# ADSP-2183xW_HPC register map
Vendor: Analog Devices; Series: ADSP-2183xW_HPC; File version: 3.0.3.517
CPU: 
Registers are 32-bit, read-write, reset 0x0 unless marked. A register's access mark holds for its fields unless they carry their own. Offsets are from the block's base; [hi:lo] are bit positions; {n}, {i} and the like mark numbered series; 'fields as' and 'values as' point back to an identical list.

## EMAC0 (part 1 of 4) — RGMII, RMII, MII Ethernet Controller
Base 0x31040000
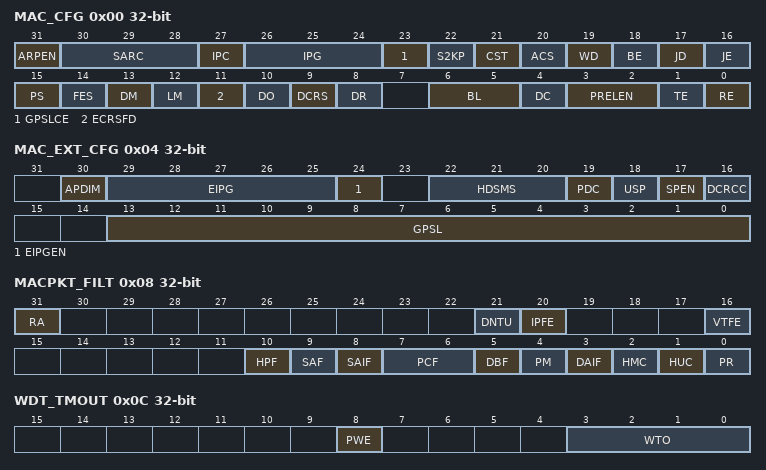
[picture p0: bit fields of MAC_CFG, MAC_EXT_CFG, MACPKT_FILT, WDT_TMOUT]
0x00 MAC_CFG — MAC Configuration Register
  [31] ARPEN — ARP Offload Enable
    0=ARPEN_DISABLE (ARP Offload is Disabled); 1=ARPEN_ENABLE (ARP Offload is Enabled)
  [30:28] SARC — Source Address Insertion or Replacement Control
    0=SA_CTRL_IN (Reserved); 2=MAC0_INS_SA (Contents of MAC Address 0 Inserted in SA Field); 3=MAC0_REP_SA (Contents of MAC Address 0 Replaces SA Field); 6=MAC1_INS_SA (Contents of MAC Address 1 Inserted in SA Field); 7=MAC1_REP_SA (Contents of MAC Address 1 Replaces SA Field)
  [27] IPC — Checksum Offload
    0=IPC_DISABLE (IP Header/payload Checksum Checking is Disabled); 1=IPC_ENABLE (IP Header/payload Checksum Checking is Enabled)
  [26:24] IPG — Inter-Packet Gap
    0=96 Bit Times IPG; 1=88 Bit Times IPG; 2=80 Bit Times IPG; 3=72 Bit Times IPG; 4=64 Bit Times IPG; 5=56 Bit Times IPG; 6=48 Bit Times IPG; 7=40 Bit Times IPG
  [23] GPSLCE — Giant Packet Size Limit Control Enable
    0=GPSLCE_DISABLE (Giant Packet Size Limit Control is Disabled); 1=GPSLCE_ENABLE (Giant Packet Size Limit Control is Enabled)
  [22] S2KP — IEEE 802.3as Support for 2K Packets
    0=S2KP_DISABLE (Support Upto 2K Packet is Disabled); 1=S2KP_ENABLE (Support Upto 2K Packet is Enabled)
  [21] CST — CRC Stripping for Type Packets
    0=CST_DISABLE (CRC Stripping for Type Packets is Disabled); 1=CST_ENABLE (CRC Stripping for Type Packets is Enabled)
  [20] ACS — Automatic Pad or CRC Stripping
    0=ACS_DISABLE (Automatic Pad or CRC Stripping is Disabled); 1=ACS_ENABLE (Automatic Pad or CRC Stripping is Enabled)
  [19] WD — Watchdog Disable
    0=WD_ENABLE (Watchdog is Enabled); 1=WD_DISABLE (Watchdog is Disabled)
  [18] BE — Packet Burst Enable
    0=BE_DISABLE (Packet Burst is Disabled); 1=BE_ENABLE (Packet Burst is Enabled)
  [17] JD — Jabber Disable
    0=JD_ENABLE (Jabber is Enabled); 1=JD_DISABLE (Jabber is Disabled)
  [16] JE — Jumbo Packet Enable
    0=JE_DISABLE (Jumbo Packet is Disabled); 1=JE_ENABLE (Jumbo Packet is Enabled)
  [15] PS — Port Select
    0=M_1000_2500M (1000 Mbps Operation); 1=M_10_100M (10 or 100 Mbps Operation)
  [14] FES — Speed
    0=M_10_1000M (10 Mbps when PS = 1; 1 Gbps when PS = 0); 1=M_100_2500M (100 Mbps when PS = 1; reserved when PS = 0)
  [13] DM — Duplex Mode
    0=HDUPLX (Half-duplex Mode); 1=FDUPLX (Full-duplex Mode)
  [12] LM — Loopback Mode
    0=LM_DISABLE (Loopback is Disabled); 1=LM_ENABLE (Loopback is Enabled)
  [11] ECRSFD — Enable Carrier Sense Before Transmission in Full-Duplex Mode
    0=ECRSFD_DISABLE (ECRSFD is Disabled); 1=ECRSFD_ENABLE (ECRSFD is Enabled)
  [10] DO — Disable Receive Own
    0=DO_ENABLE (Enable Receive Own); 1=DO_DISABLE (Disable Receive Own)
  [9] DCRS — Disable Carrier Sense During Transmission
    0=DCRS_ENABLE (Enable Carrier Sense During Transmission); 1=DCRS_DISABLE (Disable Carrier Sense During Transmission)
  [8] DR — Disable Retry
    0=DR_ENABLE (Enable Retry); 1=DR_DISABLE (Disable Retry)
  [6:5] BL — Back-Off Limit
    0=MIN_N_10 (k is Minimum of Retransmission Attempt and 10); 1=MIN_N_8 (k is Minimum of Retransmission Attempt and 8); 2=MIN_N_4 (k is Minimum of Retransmission Attempt and 4); 3=MIN_N_1 (k is Minimum of Retransmission Attempt and 1)
  [4] DC — Deferral Check
    0=DC_DISABLE (Deferral Check Function is Disabled); 1=DC_ENABLE (Deferral Check Function is Enabled)
  [3:2] PRELEN — Preamble Length for Transmit Packets
    0=M_7BYTES (7 Bytes of Preamble); 1=M_5BYTES (5 Bytes of Preamble); 2=M_3BYTES (3 Bytes of Preamble)
  [1] TE — Transmitter Enable
    0=TE_DISABLE (Transmitter is Disabled); 1=TE_ENABLE (Transmitter is Enabled)
  [0] RE — Receiver Enable
    0=RE_DISABLE (Receiver is Disabled); 1=RE_ENABLE (Receiver is Enabled)
0x04 MAC_EXT_CFG — MAC Extended Configuration Register
  [30] APDIM — ARP Packet Drop If IP Address Mismatch
    0=APDIM_DISABLE (Mux Select to Drop the Arp Packet If Target Protocol Address Mismatches IPv4 Address Disabled); 1=APDIM_ENABLE (Mux Select to Drop the Arp Packet If Target Protocol Address Mismatches IPv4 Address Enabled)
  [29:25] EIPG range 0x00000000..0x0000001F — Extended Inter-Packet Gap
  [24] EIPGEN — Extended Inter-Packet Gap Enable
    0=EIPGEN_DISABLE (Extended Inter-Packet Gap is Disabled); 1=EIPGEN_ENABLE (Extended Inter-Packet Gap is Enabled)
  [22:20] HDSMS — Maximum Size for Splitting the Header Data
    0=M_64BYTES (Maximum Size for Splitting the Header Data is 64 Bytes); 1=M_128BYTES (Maximum Size for Splitting the Header Data is 128 Bytes); 2=M_256BYTES (Maximum Size for Splitting the Header Data is 256 Bytes); 3=M_512BYTES (Maximum Size for Splitting the Header Data is 512 Bytes); 4=M_1024BYTES (Maximum Size for Splitting the Header Data is 1024 Bytes)
  [19] PDC — Packet Duplication Control
    0=PDC_DISABLE (Packet Duplication Control is Disabled); 1=PDC_ENABLE (Packet Duplication Control is Enabled)
  [18] USP — Unicast Slow Protocol Packet Detect
    0=USP_DISABLE (Unicast Slow Protocol Packet Detection is Disabled); 1=USP_ENABLE (Unicast Slow Protocol Packet Detection is Enabled)
  [17] SPEN — Slow Protocol Detection Enable
    0=SPEN_DISABLE (Slow Protocol Detection is Disabled); 1=SPEN_ENABLE (Slow Protocol Detection is Enabled)
  [16] DCRCC — Disable CRC Checking for Received Packets
    0=DCRCC_ENABLE (CRC Checking is Enabled); 1=DCRCC_DISABLE (CRC Checking is Disabled)
  [13:0] GPSL range 0x00000000..0x00003FFF — Giant Packet Size Limit
0x08 MACPKT_FILT — MAC Packet Filter Register
  [31] RA — Receive All
    0=RA_DISABLE (Receive All is Disabled); 1=RA_ENABLE (Receive All is Enabled)
  [21] DNTU — Drop Non-TCP/UDP Over IP Packets
    0=FWD (Forward Non-TCP/UDP Over IP Packets); 1=DROP (Drop Non-TCP/UDP Over IP Packets)
  [20] IPFE — Layer 3 and Layer 4 Filter Enable
    0=IPFE_DISABLE (Layer 3 and Layer 4 Filters are Disabled); 1=IPFE_ENABLE (Layer 3 and Layer 4 Filters are Enabled)
  [16] VTFE — VLAN Tag Filter Enable
    0=VTFE_DISABLE (VLAN Tag Filter is Disabled); 1=VTFE_ENABLE (VLAN Tag Filter is Enabled)
  [10] HPF — Hash or Perfect Filter
    0=HPF_DISABLE (Hash or Perfect Filter is Disabled); 1=HPF_ENABLE (Hash or Perfect Filter is Enabled)
  [9] SAF — Source Address Filter Enable
    0=SAF_DISABLE (SA Filtering is Disabled); 1=SAF_ENABLE (SA Filtering is Enabled)
  [8] SAIF — SA Inverse Filtering
    0=SAIF_DISABLE (SA Inverse Filtering is Disabled); 1=SAIF_ENABLE (SA Inverse Filtering is Enabled)
  [7:6] PCF — Pass Control Packets
    0=FLTR_ALL (MAC filters all control packets from reaching the application); 1=FW_XCPT_PAU (MAC forwards all control packets except pause packets to the application even if they fail the address filter); 2=FW_ALL (MAC forwards all control packets to the application even if they fail the address filter); 3=FW_PASS (MAC forwards the control packets that pass the address filter)
  [5] DBF — Disable Broadcast Packets
    0=DBF_ENABLE (Enable Broadcast Packets); 1=DBF_DISABLE (Disable Broadcast Packets)
  [4] PM — Pass All Multicast
    0=PM_DISABLE (Pass All Multicast is Disabled); 1=PM_ENABLE (Pass All Multicast is Enabled)
  [3] DAIF — DA Inverse Filtering
    0=DAIF_DISABLE (DA Inverse Filtering is Disabled); 1=DAIF_ENABLE (DA Inverse Filtering is Enabled)
  [2] HMC — Hash Multicast
    0=HMC_DISABLE (Hash Multicast is Disabled); 1=HMC_ENABLE (Hash Multicast is Enabled)
  [1] HUC — Hash Unicast
    0=HUC_DISABLE (Hash Unicast is Disabled); 1=HUC_ENABLE (Hash Unicast is Enabled)
  [0] PR — Promiscuous Mode
    0=PR_DISABLE (Promiscuous Mode is Disabled); 1=PR_ENABLE (Promiscuous Mode is Enabled)
0x0C WDT_TMOUT — Watchdog Timeout Register
  [8] PWE
    0=PWE_DISABLE (Programmable Watchdog is disabled.); 1=PWE_ENABLE (Programmable Watchdog is enabled.)
  [3:0] WTO
    {v}=WTO_M_{v+2}KBYTES ({v+2} KB.) (v=0..13); 14=WTO_M_16383BYTES (16383 Bytes.)
0x10 HASHTBL_REG0 — Hash Table Register 0
  [31:0] HT31T0 range 0x00000000..0xFFFFFFFF — MAC Hash Table First 32 Bits
0x14 HASHTBL_REG1 — Hash Table Register 1
  [31:0] HT63T32 range 0x00000000..0xFFFFFFFF — MAC Hash Table Second 32 Bits
0x18 HASHTBL_REG2 — Hash Table Register 2
  [31:0] HT95T64 range 0x00000000..0xFFFFFFFF — MAC Hash Table Third 32 Bits
0x1C HASHTBL_REG3 — Hash Table Register 3
  [31:0] HT127T96 range 0x00000000..0xFFFFFFFF — MAC Hash Table Fourth 32 Bits
0x20 HASHTBL_REG4 — Hash Table Register 4
  [31:0] HT159T128 range 0x00000000..0xFFFFFFFF — MAC Hash Table Fifth 32 Bits
0x24 HASHTBL_REG5 — Hash Table Register 5
  [31:0] HT191T160 range 0x00000000..0xFFFFFFFF — MAC Hash Table Sixth 32 Bits
0x28 HASHTBL_REG6 — Hash Table Register 6
  [31:0] HT223T192 range 0x00000000..0xFFFFFFFF — MAC Hash Table Seventh 32 Bits
0x2C HASHTBL_REG7 — Hash Table Register 7
  [31:0] HT255T224 range 0x00000000..0xFFFFFFFF — MAC Hash Table Eighth 32 Bits
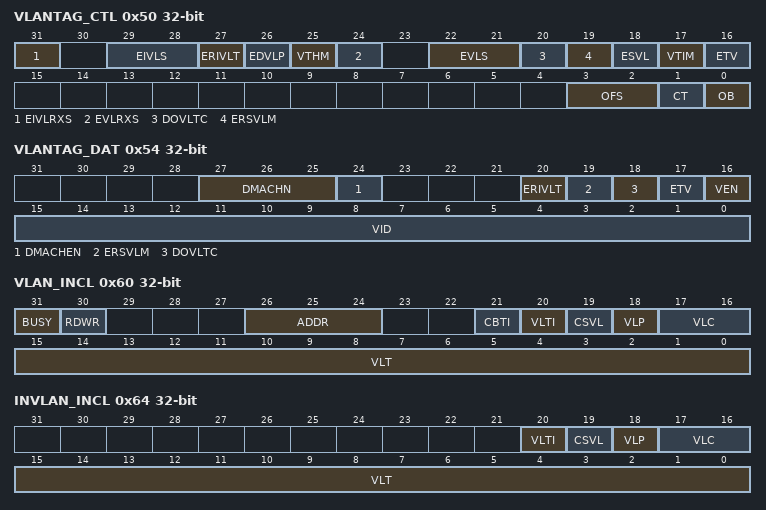
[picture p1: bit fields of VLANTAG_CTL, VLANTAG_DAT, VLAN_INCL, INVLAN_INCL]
0x50 VLANTAG_CTL — VLAN Tag Control Register
  [31] EIVLRXS — Enable Inner VLAN Tag in Rx Status
    0=EIVLRXS_DISABLE (Inner VLAN Tag in Rx Status is Disabled); 1=EIVLRXS_ENABLE (Inner VLAN Tag in Rx Status is Enabled)
  [29:28] EIVLS — Enable Inner VLAN Tag Stripping on Receive
    0=EIVLS_DONOT (Do Not Strip); 1=EIVLS_IFPASS (Strip If VLAN Filter Passes); 2=EIVLS_IFFAIL (Strip If VLAN Filter Fails); 3=EIVLS_ALWAYS (Always Strip)
  [27] ERIVLT — Enable Inner VLAN Tag Comparison
    0=ERIVLT_DISABLE (Inner VLAN Tag is Disabled); 1=ERIVLT_ENABLE (Inner VLAN Tag is Enabled)
  [26] EDVLP — Enable Double VLAN Processing
    0=EDVLP_DISABLE (Double VLAN Processing is Disabled); 1=EDVLP_ENABLE (Double VLAN Processing is Enabled)
  [25] VTHM — VLAN Tag Hash Table Match Enable
    0=VTHM_DISABLE (VLAN Tag Hash Table Match is Disabled); 1=VTHM_ENABLE (VLAN Tag Hash Table Match is Enabled)
  [24] EVLRXS — Enable VLAN Tag in Rx Status
    0=EVLRXS_DISABLE (VLAN Tag in Rx Status is Disabled); 1=EVLRXS_ENABLE (VLAN Tag in Rx Status is Enabled)
  [22:21] EVLS — Enable VLAN Tag Stripping on Receive
    0=EVLS_DONOT (Do Not Strip); 1=EVLS_IFPASS (Strip If VLAN Filter Passes); 2=EVLS_IFFAIL (Strip If VLAN Filter Fails); 3=EVLS_ALWAYS (Always Strip)
  [20] DOVLTC — Disable VLAN Type Check for VLAN Hash Filtering
    0=DOVLTC_ENABLE (VLAN Type Check is Enabled); 1=DOVLTC_DISABLE (VLAN Type Check is Disabled)
  [19] ERSVLM — Enable Receive S-VLAN Match for VLAN Hash Filtering
    0=ERSVLM_DISABLE (Receive S-VLAN Match is Disabled); 1=ERSVLM_ENABLE (Receive S-VLAN Match is Enabled)
  [18] ESVL — Enable S-VLAN
    0=ESVL_DISABLE (S-VLAN is Disabled); 1=ESVL_ENABLE (S-VLAN is Enabled)
  [17] VTIM — VLAN Tag Inverse Match Enable
    0=VTIM_DISABLE (VLAN Tag Inverse Match is Disabled); 1=VTIM_ENABLE (VLAN Tag Inverse Match is Enabled)
  [16] ETV — Enable 12-Bit VLAN Tag Comparison for VLAN Hash Filtering
    0=ETV_DISABLE (12-Bit VLAN Tag Comparison is Disabled); 1=ETV_ENABLE (12-Bit VLAN Tag Comparison is Enabled)
  [3:2] OFS range 0x00000000..0x00000003 — Offset
  [1] CT — Command Type
    0=WRITE (Write Operation); 1=READ (Read Operation)
  [0] OB — Operation Busy
    0=OB_DISABLE (Operation Busy is Disabled); 1=OB_ENABLE (Operation Busy is Enabled)
0x54 VLANTAG_DAT — VLAN Tag Indirect Access Data Register
  [27:25] DMACHN range 0x00000000..0x00000007 — DMA Channel Number
  [24] DMACHEN — DMA Channel Number Enable
    0=DMACHEN_DISABLE (DMA Channel Number is Disabled); 1=DMACHEN_ENABLE (DMA Channel Number is Enabled)
  [20] ERIVLT — Enable Inner VLAN Tag Comparison
    0=ERIVLT_DISABLE (Inner VLAN Tag Comparison is Disabled); 1=ERIVLT_ENABLE (Inner VLAN Tag Comparison is Enabled)
  [19] ERSVLM — Enable S-VLAN Match for Received Frames
    values as VLANTAG_CTL.ERSVLM
  [18] DOVLTC — Disable VLAN Type Comparison
    0=DOVLTC_ENABLE (VLAN Type Comparison is Enabled); 1=DOVLTC_DISABLE (VLAN Type Comparison is Disabled)
  [17] ETV — 12bits or 16bits VLAN Comparison
    0=M_16BIT (16 Bit VLAN Comparison); 1=M_12BIT (12 Bit VLAN Comparison)
  [16] VEN — VLAN Tag Enable
    0=VEN_DISABLE (VLAN Tag is Disabled); 1=VEN_ENABLE (VLAN Tag is Enabled)
  [15:0] VID range 0x00000000..0x0000FFFF — VLAN Tag ID
0x58 VLAN_HASHTBL — VLAN Hash Table Register
  [15:0] VLHT range 0x00000000..0x0000FFFF — VLAN Hash Table
0x60 VLAN_INCL — VLAN Tag Inclusion or Replacement Register
  [31] BUSY ro
    0=BUSY_INACTIVE (Busy Status Not Detected); 1=BUSY_ACTIVE (Busy Status Detected)
  [30] RDWR — Read Write Control
    0=READ (Read Operation of Indirect Access); 1=WRITE (Write Operation of Indirect Access)
  [26:24] ADDR range 0x00000000..0x00000007 — Address
  [21] CBTI — Channel Based Tag Insertion
    0=CBTI_DISABLE (Channel Based Tag Insertion is Disabled); 1=CBTI_ENABLE (Channel Based Tag Insertion is Enabled)
  [20] VLTI — VLAN Tag Input
    0=VLTI_DISABLE (VLAN Tag Input is Disabled); 1=VLTI_ENABLE (VLAN Tag Input is Enabled)
  [19] CSVL — C-VLAN or S-VLAN
    0=CVLAN (C-VLAN Type (0x8100) is Inserted or Replaced); 1=SVLAN (S-VLAN Type (0x88A8) is Inserted or Replaced)
  [18] VLP — VLAN Priority Control
    0=VLP_DISABLE (VLAN Priority Control is Disabled); 1=VLP_ENABLE (VLAN Priority Control is Enabled)
  [17:16] VLC — VLAN Tag Control in Transmit Packets
    0=NONE (No VLAN Tag Deletion, Insertion, or Replacement); 1=DELETE (VLAN Tag Deletion); 2=INSERT (VLAN Tag Insertion); 3=REPLACE (VLAN Tag Replacement)
  [15:0] VLT range 0x00000000..0x0000FFFF — VLAN Tag for Transmit Packets
0x64 INVLAN_INCL — Inner VLAN Tag Inclusion or Replacement Register
  [20] VLTI — VLAN Tag Input
    values as VLAN_INCL.VLTI
  [19] CSVL — C-VLAN or S-VLAN
    0=CVLAN (C-VLAN Type (0x8100) is Inserted); 1=SVLAN (S-VLAN Type (0x88A8) is Inserted)
  [18] VLP — VLAN Priority Control
    values as VLAN_INCL.VLP
  [17:16] VLC — VLAN Tag Control in Transmit Packets
    values as VLAN_INCL.VLC
  [15:0] VLT range 0x00000000..0x0000FFFF — VLAN Tag for Transmit Packets
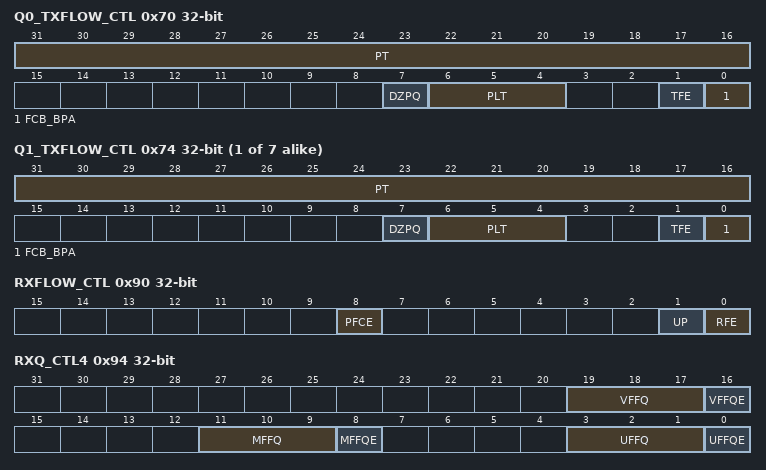
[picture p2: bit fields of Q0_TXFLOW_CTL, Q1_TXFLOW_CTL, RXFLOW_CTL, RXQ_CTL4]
0x70 Q0_TXFLOW_CTL — Queue 0 Transmit Flow Control Register
  [31:16] PT range 0x00000000..0x0000FFFF — Pause Time
  [7] DZPQ — Disable Zero-Quanta Pause
    0=DZPQ_ENABLE (Zero-Quanta Pause Packet Generation is Enabled); 1=DZPQ_DISABLE (Zero-Quanta Pause Packet Generation is Disabled)
  [6:4] PLT — Pause Low Threshold
    0=PT4 (Pause Time Minus 4 Slot Times); 1=PT28 (Pause Time Minus 28 Slot Times); 2=PT36 (Pause Time Minus 36 Slot Times); 3=PT144 (Pause Time Minus 144 Slot Times); 4=PT256 (Pause Time Minus 256 Slot Times); 5=PT512 (Pause Time Minus 512 Slot Times)
  [1] TFE — Transmit Flow Control Enable
    0=TFE_DISABLE (Transmit Flow Control is Disabled); 1=TFE_ENABLE (Transmit Flow Control is Enabled)
  [0] FCB_BPA — Flow Control Busy or Backpressure Activate
    0=FCB_BPA_DISABLE (Flow Control Busy or Backpressure Activate is Disabled); 1=FCB_BPA_ENABLE (Flow Control Busy or Backpressure Activate is Enabled)
{0x70+4i} Q{i}_TXFLOW_CTL (i=1..7) — Queue [i] Transmit Flow Control Register
  [31:16] PT range 0x00000000..0x0000FFFF — Pause Time
  [7] DZPQ — Disable Zero-Quanta Pause
    values as Q0_TXFLOW_CTL.DZPQ
  [6:4] PLT — Pause Low Threshold
    0=PT4 (PT - 4 Slot Times); 1=PT28 (PT - 28 Slot Times); 2=PT36 (PT - 36 Slot Times); 3=PT144 (PT - 144 Slot Times); 4=PT256 (PT - 256 Slot Times); 5=PT512 (PT - 512 Slot Times)
  [1] TFE — Transmit Flow Control Enable
    values as Q0_TXFLOW_CTL.TFE
  [0] FCB_BPA — Flow Control Busy
    values as Q0_TXFLOW_CTL.FCB_BPA
0x90 RXFLOW_CTL — Receive Flow Control Register
  [8] PFCE — Priority Based Flow Control Enable
    0=PFCE_DISABLE (Priority Based Flow Control is Disabled); 1=PFCE_ENABLE (Priority Based Flow Control is Enabled)
  [1] UP — Unicast Pause Packet Detect
    0=UP_DISABLE (Unicast Pause Packet Detect Disabled); 1=UP_ENABLE (Unicast Pause Packet Detect Enabled)
  [0] RFE — Receive Flow Control Enable
    0=RFE_DISABLE (Receive Flow Control is Disabled); 1=RFE_ENABLE (Receive Flow Control is Enabled)
0x94 RXQ_CTL4 — Receive Queue Control 4 Register
  [19:17] VFFQ range 0x00000000..0x00000007 — VLAN Tag Filter Fail Packets Queue
  [16] VFFQE — VLAN Tag Filter Fail Packets Queuing Enable
    0=VFFQE_DISABLE (VLAN Tag Filter Fail Packets Queuing is Disabled); 1=VFFQE_ENABLE (VLAN Tag Filter Fail Packets Queuing is Enabled)
  [11:9] MFFQ range 0x00000000..0x00000007 — Multicast Address Filter Fail Packets Queue.
  [8] MFFQE — Multicast Address Filter Fail Packets Queuing Enable.
    0=MFFQE_DISABLE (Multicast Address Filter Fail Packets Queuing is Disabled); 1=MFFQE_ENABLE (Multicast Address Filter Fail Packets Queuing is Enabled)
  [3:1] UFFQ range 0x00000000..0x00000007 — Unicast Address Filter Fail Packets Queue.
  [0] UFFQE — Unicast Address Filter Fail Packets Queuing Enable.
    0=UFFQE_DISABLE (Unicast Address Filter Fail Packets Queuing is Disabled); 1=UFFQE_ENABLE (Unicast Address Filter Fail Packets Queuing is Enabled)
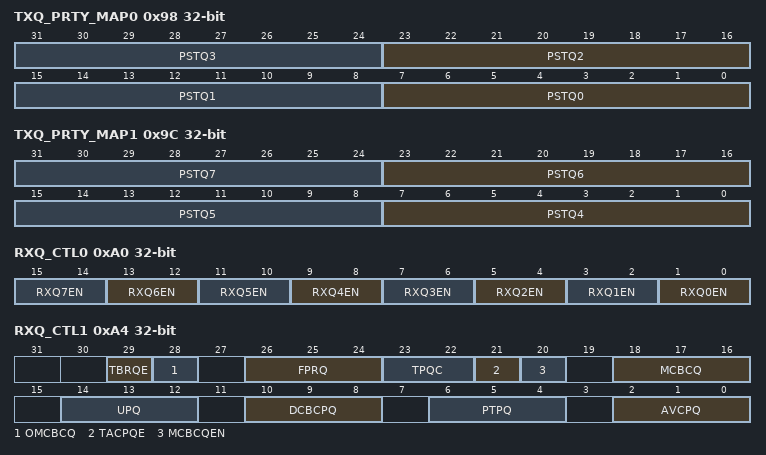
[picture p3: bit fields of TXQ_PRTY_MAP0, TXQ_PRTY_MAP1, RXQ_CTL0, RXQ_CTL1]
0x98 TXQ_PRTY_MAP0 — Transmit Queue Priority Mapping 0 Register
  [8n+7:8n] PSTQ{n} range 0x00000000..0x000000FF (n=0..3) — Priorities Selected in Transmit Queue {n}
0x9C TXQ_PRTY_MAP1 — Transmit Queue Priority Mapping 1 Register
  [8n-25:8n-32] PSTQ{n} range 0x00000000..0x000000FF (n=4..7) — Priorities Selected in Transmit Queue {n}
0xA0 RXQ_CTL0 — Receive Queue Control 0 Register
  [2n+1:2n] RXQ{n}EN (n=0..7) — Receive Queue {n} Enable
    0=RXQ{n}EN_DISABLE (Queue Not Enabled); 1=RXQ{n}EN_EN_AV (Queue Enabled for AV); 2=RXQ{n}EN_EN_DCB_GEN (Queue Enabled for DCB/Generic)
0xA4 RXQ_CTL1 — Receive Queue Control 1 Register
  [29] TBRQE range 0x00000000..0x00000001 — Type Field Based Rx Queuing Enable
  [28] OMCBCQ — Over-riding MC-BC Queue Priority Select
    0=OMCBCQ_DISABLE (Overriding MCBCQ Priority Disabled); 1=OMCBCQ_ENABLE (Overriding MCBCQ Priority Enabled)
  [26:24] FPRQ range 0x00000000..0x00000007 — Frame Preemption Residue Queue
  [23:22] TPQC range 0x00000000..0x00000003 — Tagged PTP Over Ethernet Packets Queuing Control.
  [21] TACPQE — Tagged AV Control Packets Queuing Enable.
    0=TACPQE_DISABLE (Tagged AV Control Packets Queuing is Disabled); 1=TACPQE_ENABLE (Tagged AV Control Packets Queuing is Enabled)
  [20] MCBCQEN — Multicast and Broadcast Queue Enable
    0=MCBCQEN_DISABLE (Multicast and Broadcast Queue is Disabled); 1=MCBCQEN_ENABLE (Multicast and Broadcast Queue is Enabled)
  [18:16] MCBCQ — Multicast and Broadcast Queue
    {v}=MCBCQ_QUEUE{v} (Receive Queue {v}) (v=0..7)
  [14:12] UPQ — Untagged Packet Queue
    {v}=UPQ_QUEUE{v} (Receive Queue {v}) (v=0..7)
  [10:8] DCBCPQ — DCB Control Packets Queue
    {v}=DCBCPQ_QUEUE{v} (Receive Queue {v}) (v=0..7)
  [6:4] PTPQ — PTP Packets Queue
    {v}=PTPQ_QUEUE{v} (Receive Queue {v}) (v=0..7)
  [2:0] AVCPQ — AV Untagged Control Packets Queue
    {v}=AVCPQ_QUEUE{v} (Receive Queue {v}) (v=0..7)
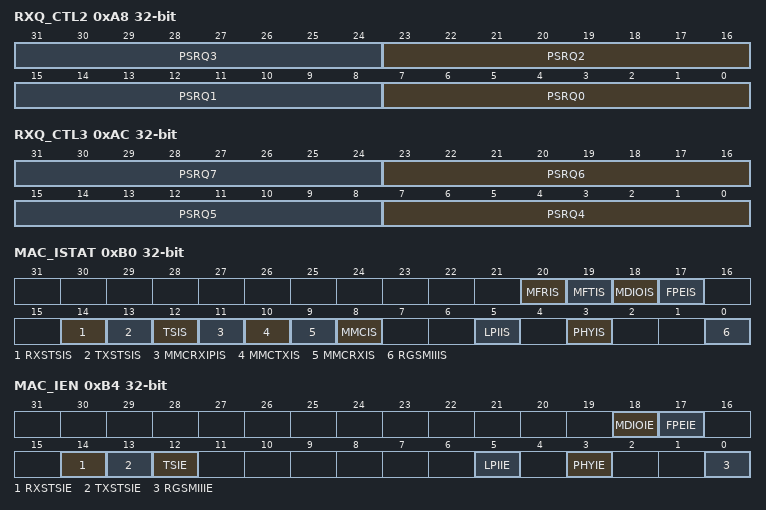
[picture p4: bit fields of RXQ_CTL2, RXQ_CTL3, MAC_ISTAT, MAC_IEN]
0xA8 RXQ_CTL2 — Receive Queue Control 2 Register
  [8n+7:8n] PSRQ{n} range 0x00000000..0x000000FF (n=0..3) — Priorities Selected in the Receive Queue {n}
0xAC RXQ_CTL3 — Receive Queue Control 3 Register
  [8n-25:8n-32] PSRQ{n} range 0x00000000..0x000000FF (n=4..7) — Priorities Selected in the Receive Queue {n}
0xB0 MAC_ISTAT — MAC Interrupt Status Register
  [20] MFRIS ro — MMC FPE Receive Interrupt Status
    0=MFRIS_INACTIVE (MMC FPE Receive Interrupt Status Not Active); 1=MFRIS_ACTIVE (MMC FPE Receive Interrupt Status Active)
  [19] MFTIS ro — MMC FPE Transmit Interrupt Status
    0=MFTIS_INACTIVE (MMC FPE Transmit Interrupt Status Not Active); 1=MFTIS_ACTIVE (MMC FPE Transmit Interrupt Status Active)
  [18] MDIOIS ro — MDIO Interrupt Status
    0=MDIOIS_INACTIVE (MDIO Interrupt Status Not Active); 1=MDIOIS_ACTIVE (MDIO Interrupt Status Active)
  [17] FPEIS ro — Frame Preemption Interrupt Status
    0=FPEIS_INACTIVE (Frame Preemption Interrupt Status Not Active); 1=FPEIS_ACTIVE (Frame Preemption Interrupt Status Active)
  [14] RXSTSIS ro — Receive Status Interrupt
    0=RXSTSIS_INACTIVE (Receive Interrupt Status Not Active); 1=RXSTSIS_ACTIVE (Receive Interrupt Status Active)
  [13] TXSTSIS ro — Transmit Status Interrupt
    0=TXSTSIS_INACTIVE (Status Not Active); 1=TXSTSIS_ACTIVE (Status Active)
  [12] TSIS ro — Time Stamp Interrupt Status
    0=TSIS_INACTIVE (Status Not Active); 1=TSIS_ACTIVE (Status Active)
  [11] MMCRXIPIS ro — MMC Receive Checksum Offload Interrupt Status
    0=MMCRXIPIS_INACTIVE (MMC Receive Checksum Offload Interrupt Status Not Active); 1=MMCRXIPIS_ACTIVE (MMC Receive Checksum Offload Interrupt Status Active)
  [10] MMCTXIS ro — MMC Transmit Interrupt Status
    0=MMCTXIS_INACTIVE (MMC Transmit Interrupt Status Not Active); 1=MMCTXIS_ACTIVE (MMC Transmit Interrupt Status Active)
  [9] MMCRXIS ro — MMC Receive Interrupt Status
    0=MMCRXIS_INACTIVE (MMC Receive Interrupt Status Not Active); 1=MMCRXIS_ACTIVE (MMC Receive Interrupt Status Active)
  [8] MMCIS ro — MMC Interrupt Status
    0=MMCIS_INACTIVE (MMC Interrupt Status Not Active); 1=MMCIS_ACTIVE (MMC Interrupt Status Active)
  [5] LPIIS ro — LPI Interrupt Status
    0=LPIIS_INACTIVE (LPI Interrupt Status Not Active); 1=LPIIS_ACTIVE (LPI Interrupt Status Active)
  [3] PHYIS ro — PHY Interrupt
    0=PHYIS_INACTIVE (PHY Interrupt Not Detected); 1=PHYIS_ACTIVE (PHY Interrupt Detected)
  [0] RGSMIIIS ro — RGMII or SMII Interrupt Status
    0=RGSMIIIS_INACTIVE (RGMII or SMII Interrupt Status is Not Active); 1=RGSMIIIS_ACTIVE (RGMII or SMII Interrupt Status is Active)
0xB4 MAC_IEN — MAC Interrupt Enable Register
  [18] MDIOIE — MDIO Interrupt Enable
    0=MDIOIE_DISABLE (MDIO Interrupt is Disabled); 1=MDIOIE_ENABLE (MDIO Interrupt is Enabled)
  [17] FPEIE — Frame Preemption Interrupt Enable
    0=FPEIE_DISABLE (Frame Preemption Interrupt is Disabled); 1=FPEIE_ENABLE (Frame Preemption Interrupt is Enabled)
  [14] RXSTSIE — Receive Status Interrupt Enable
    0=RXSTSIE_DISABLE (Receive Status Interrupt is Disabled); 1=RXSTSIE_ENABLE (Receive Status Interrupt is Enabled)
  [13] TXSTSIE — Transmit Status Interrupt Enable
    0=TXSTSIE_DISABLE (Disable); 1=TXSTSIE_ENABLE (Enable)
  [12] TSIE — Timestamp Interrupt Enable
    0=TSIE_DISABLE (Disable); 1=TSIE_ENABLE (Enable)
  [5] LPIIE — LPI Interrupt Enable
    0=LPIIE_DISABLE (LPI Interrupt is Disabled); 1=LPIIE_ENABLE (LPI Interrupt is Enabled)
  [3] PHYIE — PHY Interrupt Enable
    0=PHYIE_DISABLE (PHY Interrupt is Disabled); 1=PHYIE_ENABLE (PHY Interrupt is Enabled)
  [0] RGSMIIIE — RGMII or SMII Interrupt Enable
    0=RGSMIIIE_DISABLE (RGMII or SMII Interrupt is Disabled); 1=RGSMIIIE_ENABLE (RGMII or SMII Interrupt is Enabled)
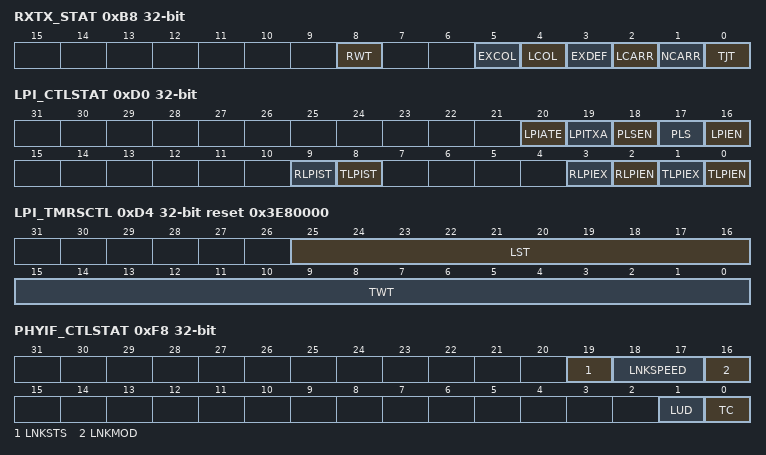
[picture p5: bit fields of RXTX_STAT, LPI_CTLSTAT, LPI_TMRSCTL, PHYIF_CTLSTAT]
0xB8 RXTX_STAT — Receive Transmit Status Register
  [8] RWT ro — Receive Watchdog Timeout
    0=RWT_INACTIVE (No Receive Watchdog Timeout); 1=RWT_ACTIVE (Receive Watchdog Timed Out)
  [5] EXCOL ro — Excessive Collisions
    0=EXCOL_INACTIVE (No Collision); 1=EXCOL_ACTIVE (Excessive Collision is Sensed)
  [4] LCOL ro — Late Collision
    0=LCOL_INACTIVE (No Collision); 1=LCOL_ACTIVE (Late Collision is Sensed)
  [3] EXDEF ro — Excessive Deferral
    0=EXDEF_INACTIVE (No Excessive Deferral); 1=EXDEF_ACTIVE (Excessive Deferral)
  [2] LCARR ro — Loss of Carrier
    0=LCARR_INACTIVE (Carrier is Present); 1=LCARR_ACTIVE (Loss of Carrier)
  [1] NCARR ro — No Carrier
    0=NCARR_INACTIVE (Carrier is Present); 1=NCARR_ACTIVE (No Carrier)
  [0] TJT ro — Transmit Jabber Timeout
    0=TJT_INACTIVE (No Transmit Jabber Timeout); 1=TJT_ACTIVE (Transmit Jabber Timeout Occurred)
0xD0 LPI_CTLSTAT — LPI Control and Status Register
  [20] LPIATE — LPI Timer Enable
    0=LPIATE_DISABLE (LPI Timer is Disabled); 1=LPIATE_ENABLE (LPI Timer is Enabled)
  [19] LPITXA — LPI Tx Automate
    0=LPITXA_DISABLE (LPI Tx Automate is Disabled); 1=LPITXA_ENABLE (LPI Tx Automate is Enabled)
  [18] PLSEN — PHY Link Status Enable
    0=PLSEN_DISABLE (PHY Link Status is Disabled); 1=PLSEN_ENABLE (PHY Link Status is Enabled)
  [17] PLS — PHY Link Status
    0=PLS_DISABLE (Link is Down); 1=PLS_ENABLE (Link is Okay (UP))
  [16] LPIEN — LPI Enable
    0=LPIEN_DISABLE (LPI State is Disabled); 1=LPIEN_ENABLE (LPI State is Enabled)
  [9] RLPIST ro — Receive LPI State
    0=RLPIST_INACTIVE (Receive LPI State Not Detected); 1=RLPIST_ACTIVE (Receive LPI State Detected)
  [8] TLPIST ro — Transmit LPI State
    0=TLPIST_INACTIVE (Transmit LPI State Not Detected); 1=TLPIST_ACTIVE (Transmit LPI State Detected)
  [3] RLPIEX ro — Receive LPI Exit
    0=RLPIEX_INACTIVE (Receive LPI Exit Not Detected); 1=RLPIEX_ACTIVE (Receive LPI Exit Detected)
  [2] RLPIEN ro — Receive LPI Entry
    0=RLPIEN_INACTIVE (Receive LPI Entry Not Detected); 1=RLPIEN_ACTIVE (Receive LPI Entry Detected)
  [1] TLPIEX ro — Transmit LPI Exit
    0=TLPIEX_INACTIVE (Transmit LPI Exit Not Detected); 1=TLPIEX_ACTIVE (Transmit LPI Exit Detected)
  [0] TLPIEN ro — Transmit LPI Entry
    0=TLPIEN_INACTIVE (Transmit LPI Entry Not Detected); 1=TLPIEN_ACTIVE (Transmit LPI Entry Detected)
0xD4 LPI_TMRSCTL reset 0x3E80000 — LPI Timers Control Register
  [25:16] LST range 0x00000000..0x000003FF — LPI LS Timer
  [15:0] TWT range 0x00000000..0x0000FFFF — LPI TW Timer
0xD8 LPI_ENTR_TMR — Transmit LPI Entry Timer Register
  [19:3] LPIET range 0x00000000..0x0001FFFF — LPI Entry Timer
0xDC ONEUS_TIC_CNT reset 0x63 — LPI One Microsecond Tic Counter Register
  [11:0] TIC_1US_CNTR range 0x00000000..0x00000FFF — 1US TIC Counter
0xF8 PHYIF_CTLSTAT — PHY Interface Control and Status Register
  [19] LNKSTS ro — Link Status
    0=LNKSTS_INACTIVE (Link Down); 1=LNKSTS_ACTIVE (Link up)
  [18:17] LNKSPEED ro — Link Speed
    0=M_2500K (2.5 MHz); 1=M_25M (25 MHz); 2=M_125M (125 MHz)
  [16] LNKMOD ro — Link Mode
    0=HDUPLX (Half-duplex Mode); 1=FDUPLX (Full-duplex Mode)
  [1] LUD — Link Up or Down
    0=LINKDOWN; 1=LINKUP
  [0] TC — Transmit Configuration in RGMII
    0=TC_DISABLE (Disable Transmit Configuration in RGMII); 1=TC_ENABLE (Enable Transmit Configuration in RGMII)
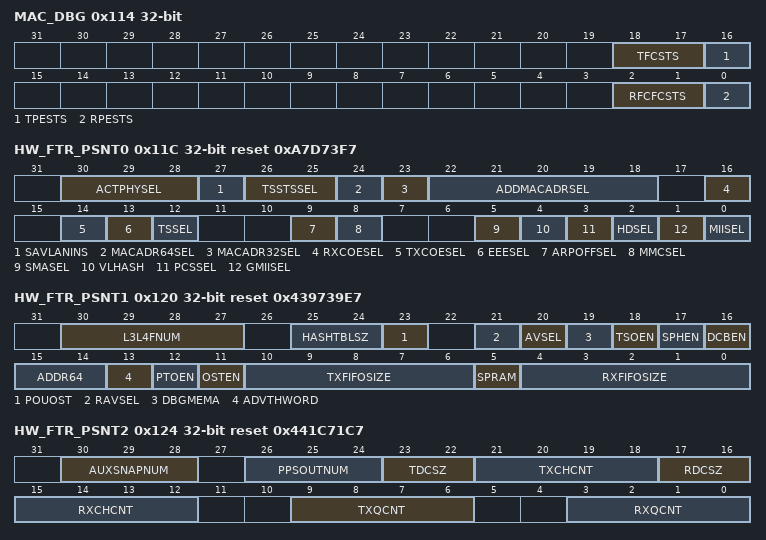
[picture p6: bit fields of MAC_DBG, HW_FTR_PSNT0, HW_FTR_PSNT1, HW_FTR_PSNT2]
0x114 MAC_DBG — Debug Register
  [18:17] TFCSTS ro — MAC Transmit Packet Controller Status
    0=IDLE (Idle State); 1=WAITING (Waiting for One of the Following: Status of the Previous Packet OR IPG or Back off Period to Be Over); 2=GEN_TX_PAU (Generating and Transmitting a Pause Control Packet (in Full-Duplex Mode)); 3=TRNSFR (Transferring Input Packet for Transmission)
  [16] TPESTS ro — MAC GMII or MII Transmit Protocol Engine Status
    0=TPESTS_INACTIVE (MAC GMII or MII Transmit Protocol Engine Status Not Detected); 1=TPESTS_ACTIVE (MAC GMII or MII Transmit Protocol Engine Status Detected)
  [2:1] RFCFCSTS ro — MAC Receive Packet Controller FIFO Status
  [0] RPESTS ro — MAC GMII or MII Receive Protocol Engine Status
    0=RPESTS_INACTIVE (MAC GMII or MII Receive Protocol Engine Status Not Detected); 1=RPESTS_ACTIVE (MAC GMII or MII Receive Protocol Engine Status Detected)
0x11C HW_FTR_PSNT0 reset 0xA7D73F7 — Hardware Feature Presence Register 0
  [30:28] ACTPHYSEL ro — Active PHY Selected
    0=GMII_MII (GMII or MII); 1=RGMII; 2=SGMII; 3=TBI; 4=RMII; 5=RTBI; 6=SMII; 7=REVMIII
  [27] SAVLANINS ro — Source Address or VLAN Insertion Enable
    0=SAVLANINS_INACTIVE (Source Address or VLAN Insertion Enable Option is Not Selected); 1=SAVLANINS_ACTIVE (Source Address or VLAN Insertion Enable Option is Selected)
  [26:25] TSSTSSEL ro — Timestamp System Time Source
    0=INTRNL (Internal); 1=EXTRNL (External); 2=BOTH
  [24] MACADR64SEL ro — MAC Addresses 64-127 Selected
    0=MACADR64SEL_INACTIVE (MAC Addresses 64-127 Select Option is Not Selected); 1=MACADR64SEL_ACTIVE (MAC Addresses 64-127 Select Option is Selected)
  [23] MACADR32SEL ro — MAC Addresses 32-63 Selected
    0=MACADR32SEL_INACTIVE (MAC Addresses 32-63 Select Option is Not Selected); 1=MACADR32SEL_ACTIVE (MAC Addresses 32-63 Select Option is Selected)
  [22:18] ADDMACADRSEL ro — MAC Addresses 1-31 Selected
  [16] RXCOESEL ro — Receive Checksum Offload Enabled
    0=RXCOESEL_INACTIVE (Receive Checksum Offload Enable Option is Not Selected); 1=RXCOESEL_ACTIVE (Receive Checksum Offload Enable Option is Selected)
  [14] TXCOESEL ro — Transmit Checksum Offload Enabled
    0=TXCOESEL_INACTIVE (Transmit Checksum Offload Enable Option is Not Selected); 1=TXCOESEL_ACTIVE (Transmit Checksum Offload Enable Option is Selected)
  [13] EEESEL ro — Energy Efficient Ethernet Enabled
    0=EEESEL_INACTIVE (Energy Efficient Ethernet Enable Option is Not Selected); 1=EEESEL_ACTIVE (Energy Efficient Ethernet Enable Option is Selected)
  [12] TSSEL ro — IEEE 1588-2008 Time Stamp Enabled
    0=TSSEL_INACTIVE (Option is Not Selected); 1=TSSEL_ACTIVE (Option is Selected)
  [9] ARPOFFSEL ro — ARP Offload Enabled
    0=ARPOFFSEL_INACTIVE (ARP Offload Enable Option is Not Selected); 1=ARPOFFSEL_ACTIVE (ARP Offload Enable Option is Selected)
  [8] MMCSEL ro — RMON Module Enable
    0=MMCSEL_INACTIVE (RMON Module Enable Option is Not Selected); 1=MMCSEL_ACTIVE (RMON Module Enable Option is Selected)
  [5] SMASEL ro — SMA (MDIO) Interface
    0=SMASEL_INACTIVE (SMA (MDIO) Interface Not Selected); 1=SMASEL_ACTIVE (SMA (MDIO) Interface Selected)
  [4] VLHASH ro — VLAN Hash Filter Selected
    0=VLHASH_INACTIVE (VLAN Hash Filter Not Selected); 1=VLHASH_ACTIVE (VLAN Hash Filter Selected)
  [3] PCSSEL ro — PCS Registers (TBI, SGMII, or RTBI PHY Interface)
    0=PCSSEL_INACTIVE (No PCS Registers (TBI, SGMII, or RTBI PHY Interface)); 1=PCSSEL_ACTIVE (PCS Registers (TBI, SGMII, or RTBI PHY Interface))
  [2] HDSEL ro — Half-duplex Support
    0=HDSEL_INACTIVE (No Half-duplex Support); 1=HDSEL_ACTIVE (Half-duplex Support)
  [1] GMIISEL ro — 1000 Mbps Support
    0=GMIISEL_INACTIVE (No 1000 Mbps Support); 1=GMIISEL_ACTIVE (1000 Mbps Support)
  [0] MIISEL ro — 10 or 100 Mbps Support
    0=MIISEL_INACTIVE (No 10 or 100 Mbps Support); 1=MIISEL_ACTIVE (10 or 100 Mbps Support)
0x120 HW_FTR_PSNT1 reset 0x439739E7 — Hardware Feature Presence Register 1
  [30:27] L3L4FNUM ro — Total Number of L3 or L4 Filters
    0=NOFILT (No L3 or L4 Filter); 1=M_1FILT (1 L3 or L4 Filter); {v}=M_{v}FILT ({v} L3 or L4 Filters) (v=2..8)
  [25:24] HASHTBLSZ ro — Hash Table Size
    0=NO_HT (No Hash Table); 1=M_64 (64); 2=M_128 (128); 3=M_256 (256)
  [23] POUOST ro — One Step for PTP Over UDP/IP Feature Enable
    0=POUOST_INACTIVE (One Step for PTP Over UDP/IP Feature is Not Selected); 1=POUOST_ACTIVE (One Step for PTP Over UDP/IP Feature is Selected)
  [21] RAVSEL ro — Rx Side Only AV Feature Enable
    0=RAVSEL_INACTIVE (Rx Side Only AV Feature is Not Selected); 1=RAVSEL_ACTIVE (Rx Side Only AV Feature is Selected)
  [20] AVSEL ro — AV Feature Enable
    0=AVSEL_INACTIVE (AV Feature is Not Selected); 1=AVSEL_ACTIVE (AV Feature is Selected)
  [19] DBGMEMA ro — DMA Debug Registers Enable
    0=DBGMEMA_INACTIVE (DMA Debug Registers Option is Not Selected); 1=DBGMEMA_ACTIVE (DMA Debug Registers Option is Selected)
  [18] TSOEN ro — TCP Segmentation Offload Enable
    0=TSOEN_INACTIVE (TCP Segmentation Offload Feature is Not Selected); 1=TSOEN_ACTIVE (TCP Segmentation Offload Feature is Selected)
  [17] SPHEN ro — Split Header Feature Enable
    0=SPHEN_INACTIVE (Split Header Feature is Not Selected); 1=SPHEN_ACTIVE (Split Header Feature is Selected)
  [16] DCBEN ro — DCB Feature Enable
    0=DCBEN_INACTIVE (DCB Feature is Not Selected); 1=DCBEN_ACTIVE (DCB Feature is Selected)
  [15:14] ADDR64 ro — Address Width
    0=M_32 (32); 1=M_40 (40); 2=M_48 (48)
  [13] ADVTHWORD ro — IEEE 1588 High Word Register Enable
    0=ADVTHWORD_INACTIVE (IEEE 1588 High Word Register Option is Not Selected); 1=ADVTHWORD_ACTIVE (IEEE 1588 High Word Register Option is Selected)
  [12] PTOEN ro — PTP Offload Enable
    0=PTOEN_INACTIVE (PTP Offload Feature is Not Selected); 1=PTOEN_ACTIVE (PTP Offload Feature is Selected)
  [11] OSTEN ro — One-Step Timestamping Enable
    0=OSTEN_INACTIVE (Feature is Not Selected); 1=OSTEN_ACTIVE (Feature is Selected)
  [10:6] TXFIFOSIZE ro — MTL Transmit FIFO Size
    0=TXFIFOSIZE_M_128B (128 Bytes); 1=TXFIFOSIZE_M_256B (256 Bytes); 2=TXFIFOSIZE_M_512B (512 Bytes); 3=TXFIFOSIZE_M_1024B (1024 Bytes); 4=TXFIFOSIZE_M_2048B (2048 Bytes); 5=TXFIFOSIZE_M_4096B (4096 Bytes); 6=TXFIFOSIZE_M_8192B (8192 Bytes); 7=TXFIFOSIZE_M_16384B (16384 Bytes); 8=TXFIFOSIZE_M_32KB (32 KB); 9=TXFIFOSIZE_M_64KB (64 KB); 10=TXFIFOSIZE_M_128KB (128 KB)
  [5] SPRAM ro — Single Port RAM Enable
    0=SPRAM_INACTIVE (Single Port RAM Feature is Not Selected); 1=SPRAM_ACTIVE (Single Port RAM Feature is Selected)
  [4:0] RXFIFOSIZE ro — MTL Receive FIFO Size
    0=RXFIFOSIZE_M_128B (128 Bytes); 1=RXFIFOSIZE_M_256B (256 Bytes); 2=RXFIFOSIZE_M_512B (512 Bytes); 3=RXFIFOSIZE_M_1024B (1024 Bytes); 4=RXFIFOSIZE_M_2048B (2048 Bytes); 5=RXFIFOSIZE_M_4096B (4096 Bytes); 6=RXFIFOSIZE_M_8192B (8192 Bytes); 7=RXFIFOSIZE_M_16384B (16384 Bytes); 8=RXFIFOSIZE_M_32KB (32 KB); 9=RXFIFOSIZE_M_64KB (64 KB); 10=RXFIFOSIZE_M_128KB (128 KB); 11=RXFIFOSIZE_M_256KB (256 KB)
0x124 HW_FTR_PSNT2 reset 0x441C71C7 — Hardware Feature Presence Register 2
  [30:28] AUXSNAPNUM ro — Number of Auxiliary Snapshot Inputs
    0=NO_AUXI (No Auxiliary Input); {v}=M_{v}_AUXI ({v} Auxiliary Input) (v=1..4)
  [26:24] PPSOUTNUM ro — Number of PPS Outputs
    0=NO_PPSO (No PPS Output); {v}=M_{v}_PPSO ({v} PPS Output) (v=1..4)
  [23:22] TDCSZ ro — Tx DMA Descriptor Cache Size
  [21:18] TXCHCNT ro — Number of DMA Transmit Channels
    0=M_1TXCH (1 MTL Tx Channel); {v}=M_{v+1}TXCH ({v+1} MTL Tx Channels) (v=1..7)
  [17:16] RDCSZ ro — Rx DMA Descriptor Cache Size
  [15:12] RXCHCNT ro — Number of DMA Receive Channels
    0=M_1RXCH (1 MTL Rx Channel); {v}=M_{v+1}RXCH ({v+1} MTL Rx Channels) (v=1..7)
  [9:6] TXQCNT ro — Number of MTL Transmit Queues
    0=M_1TXQ (1 MTL Tx Queue); {v}=M_{v+1}TXQ ({v+1} MTL Tx Queues) (v=1..7)
  [3:0] RXQCNT ro — Number of MTL Receive Queues
    0=M_1RXQ (1 MTL Rx Queue); {v}=M_{v+1}RXQ ({v+1} MTL Rx Queues) (v=1..7)
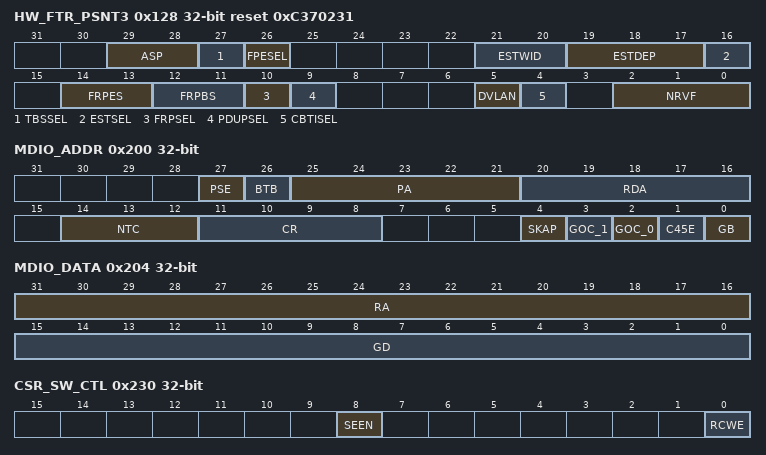
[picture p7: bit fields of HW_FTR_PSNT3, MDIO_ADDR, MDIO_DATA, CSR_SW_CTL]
0x128 HW_FTR_PSNT3 reset 0xC370231 — Hardware Feature Presence Register 3
  [29:28] ASP ro — Automotive Safety Package
    0=NONE (No Safety Features Selected); 1=ECC_ONLY (Only "ECC Protection for External Memory" Feature is Selected); 2=AS_NPPE (All the Automotive Safety Features are Selected Without the "Parity Port Enable for External Interface" Feature); 3=AS_PPE (All the Automotive Safety Features are Selected with the "Parity Port Enable for External Interface" Feature)
  [27] TBSSEL ro — Time Based Scheduling Enable
    0=TBSSEL_INACTIVE (Time Based Scheduling Enable Feature is Not Selected); 1=TBSSEL_ACTIVE (Time Based Scheduling Enable Feature is Selected)
  [26] FPESEL ro — Frame Preemption Enable
    0=FPESEL_INACTIVE (Frame Preemption Enable Feature is Not Selected); 1=FPESEL_ACTIVE (Frame Preemption Enable Feature is Selected)
  [21:20] ESTWID ro — Width of the Time Interval Field in the Gate Control List
    0=NOWIDTH (Width Not Configured); 1=WIDTH16 (16); 2=WIDTH20 (20); 3=WIDTH24 (24)
  [19:17] ESTDEP ro — Depth of the Gate Control List
    0=NODEPTH (No Depth Configured); 1=DEPTH64 (64); 2=DEPTH128 (128); 3=DEPTH256 (256); 4=DEPTH512 (512); 5=DEPTH1024 (1024)
  [16] ESTSEL ro — Enhancements to Scheduled Traffic Enable
    0=ESTSEL_INACTIVE (Enable Enhancements to Scheduling Traffic Feature is Not Selected); 1=ESTSEL_ACTIVE (Enable Enhancements to Scheduling Traffic Feature is Selected)
  [14:13] FRPES ro — Flexible Receive Parser Table Entries Size
    0=M_64ENTR (64 Entries); 1=M_128ENTR (128 Entries); 2=M_256ENTR (256 Entries)
  [12:11] FRPBS ro — Flexible Receive Parser Buffer Size
    0=M_64BYTES (64 Bytes); 1=M_128BYTES (128 Bytes); 2=M_256BYTES (256 Bytes)
  [10] FRPSEL ro — Flexible Receive Parser Selected
    0=FRPSEL_INACTIVE (Flexible Receive Parser Feature is Not Selected); 1=FRPSEL_ACTIVE (Flexible Receive Parser Feature is Selected)
  [9] PDUPSEL ro — Broadcast/Multicast Packet Duplication
    0=PDUPSEL_INACTIVE (Broadcast/Multicast Packet Duplication Feature is Not Selected); 1=PDUPSEL_ACTIVE (Broadcast/Multicast Packet Duplication Feature is Selected)
  [5] DVLAN ro — Double VLAN Tag Processing Selected
    0=DVLAN_INACTIVE (Double VLAN Option is Not Selected); 1=DVLAN_ACTIVE (Double VLAN Option is Selected)
  [4] CBTISEL ro — Queue/Channel Based VLAN Tag Insertion on Tx Enable
    0=CBTISEL_INACTIVE (Enable Queue/Channel Based VLAN Tag Insertion on Tx Feature is Not Selected); 1=CBTISEL_ACTIVE (Enable Queue/Channel Based VLAN Tag Insertion on Tx Feature is Selected)
  [2:0] NRVF ro — Number of Extended VLAN Tag Filters Enabled
    0=NO_ERVLAN (No Extended Rx VLAN Filters); 1=M_4_ERVLAN (4 Extended Rx VLAN Filters); 2=M_8_ERVLAN (8 Extended Rx VLAN Filters); 3=M_16_ERVLAN (16 Extended Rx VLAN Filters); 4=M_24_ERVLAN (24 Extended Rx VLAN Filters); 5=M_32_ERVLAN (32 Extended Rx VLAN Filters)
0x200 MDIO_ADDR — MDIO Address Register
  [27] PSE — Preamble Suppression Enable
    0=PSE_DISABLE (Preamble Suppression Disabled); 1=PSE_ENABLE (Preamble Suppression Enabled)
  [26] BTB — Back to Back Transactions
    0=BTB_DISABLE (Back to Back Transactions Disabled); 1=BTB_ENABLE (Back to Back Transactions Enabled)
  [25:21] PA range 0x00000000..0x0000001F — Physical Layer Address
  [20:16] RDA range 0x00000000..0x0000001F — Register/Device Address
  [14:12] NTC range 0x00000000..0x00000007 — Number of Trailing Clocks
  [11:8] CR range 0x00000000..0x0000000F — SCLK0 Range
  [4] SKAP — Skip Address Packet
    0=SKAP_DISABLE (Skip Address Packet is Disabled); 1=SKAP_ENABLE (Skip Address Packet is Enabled)
  [3] GOC_1 — GMII Operation Command 1
    0=GOC_1_DISABLE (GMII Operation Command 1 is Disabled); 1=GOC_1_ENABLE (GMII Operation Command 1 is Enabled)
  [2] GOC_0 — GMII Operation Command 0
    0=GOC_0_DISABLE (GMII Operation Command 0 is Disabled); 1=GOC_0_ENABLE (GMII Operation Command 0 is Enabled)
  [1] C45E — Clause 45 PHY Enable
    0=C45E_DISABLE (Clause 45 PHY is Disabled); 1=C45E_ENABLE (Clause 45 PHY is Enabled)
  [0] GB — GMII Busy
    0=GB_DISABLE (GMII Busy is Disabled); 1=GB_ENABLE (GMII Busy is Enabled)
0x204 MDIO_DATA
  [31:16] RA range 0x00000000..0x0000FFFF — Register Address
  [15:0] GD range 0x00000000..0x0000FFFF — GMII Data
0x210 ARP_ADDR — Address Resolution Protocol (ARP) Register
  [31:0] ARPPA range 0x00000000..0xFFFFFFFF — ARP Protocol Address
0x230 CSR_SW_CTL — CSR Software Control Register
  [8] SEEN — Slave Error Response Enable
    0=SEEN_DISABLE (Disable); 1=SEEN_ENABLE (Enable)
  [0] RCWE — Register Clear on Write 1 Enable
    0=RCWE_DISABLE (Disable); 1=RCWE_ENABLE (Enable)
